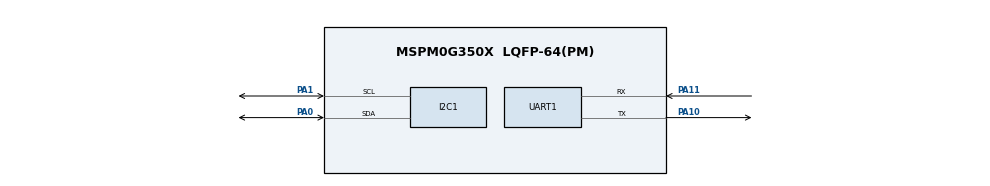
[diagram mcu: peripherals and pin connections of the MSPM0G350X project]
// @cliArgs --device "MSPM0G350X" --package "LQFP-64(PM)" --part "Default"
// @cliArgs --board /ti/boards/LP_MSPM0G3507 --rtos nortos

/**
 * Import the modules used in this configuration.
 */
const I2C    = scripting.addModule("/ti/driverlib/I2C", {}, false);
const I2C1   = I2C.addInstance();
const SYSCTL = scripting.addModule("/ti/driverlib/SYSCTL");
const UART   = scripting.addModule("/ti/driverlib/UART", {}, false);
const UART1  = UART.addInstance();

/**
 * Write custom configuration values to the imported modules.
 */
I2C1.basicEnableController       = true;
I2C1.basicTargetSecAddressEnable = true;
I2C1.enableDMAEvent1             = false;
I2C1.enableDMAEvent2             = false;
I2C1.advAnalogGlitchFilter       = "DISABLED";
I2C1.advControllerTXFIFOTRIG     = "BYTES_1";
I2C1.intController               = ["NACK","RXFIFO_TRIGGER","RX_DONE","TX_DONE"];
I2C1.$name                       = "I2C_BRIDGE";
I2C1.peripheral.sdaPin.$assign   = "PA0";
I2C1.peripheral.sclPin.$assign   = "PA1";

const Board = scripting.addModule("/ti/driverlib/Board", {}, false);

SYSCTL.clockTreeEn = true;
SYSCTL.forceDefaultClkConfig = true;

UART1.rxFifoThreshold          = "DL_UART_RX_FIFO_LEVEL_ONE_ENTRY";
UART1.enableDMARX              = false;
UART1.enableDMATX              = false;
UART1.enabledInterrupts        = ["RX"];
UART1.$name                    = "UART_BRIDGE";
UART1.peripheral.$assign       = "UART0";
UART1.peripheral.rxPin.$assign = "PA11";
UART1.peripheral.txPin.$assign = "PA10";
